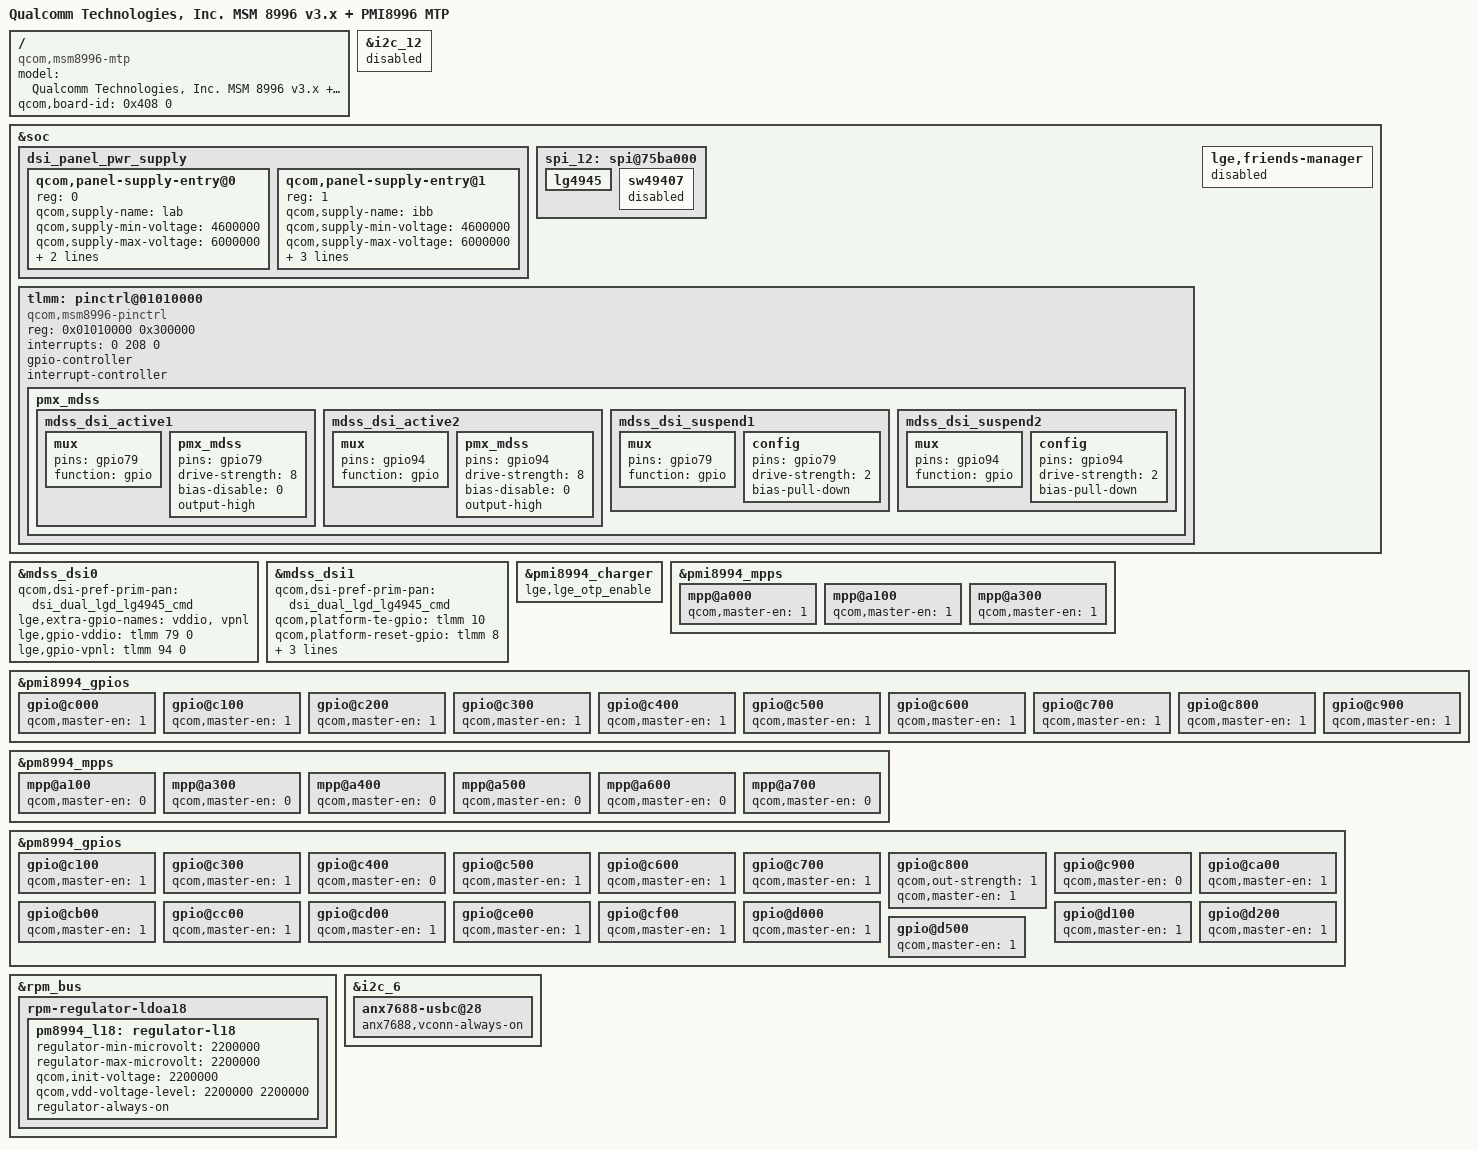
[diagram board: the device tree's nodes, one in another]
/* Copyright (c) 2015, The Linux Foundation. All rights reserved.
 *
 * This program is free software; you can redistribute it and/or modify
 * it under the terms of the GNU General Public License version 2 and
 * only version 2 as published by the Free Software Foundation.
 *
 * This program is distributed in the hope that it will be useful,
 * but WITHOUT ANY WARRANTY; without even the implied warranty of
 * MERCHANTABILITY or FITNESS FOR A PARTICULAR PURPOSE.  See the
 * GNU General Public License for more details.
 */


/dts-v1/;

#include "../../qcom/msm8996-v3.dtsi"
#include "../../qcom/msm-pmi8996.dtsi"
#include "msm8996-elsa_clr_pr.dtsi"
#include "msm8996-elsa_clr_pr-touch.dtsi"
#include "../msm8996-camera/msm8996-elsa-camera.dtsi"
#include "../msm8996-elsa_storage_type/current_storage_type.dtsi"
#include "../msm8996-sound/msm8996-elsa-sound_rev-0_1.dtsi"


/ {
	model = "Qualcomm Technologies, Inc. MSM 8996 v3.x + PMI8996 MTP";
	compatible = "qcom,msm8996-mtp", "qcom,msm8996", "qcom,mtp";
	qcom,board-id = <0x408 0>;
};

&i2c_12 {
	status = "disabled";
};

/* Display Function */
&soc {
	dsi_panel_pwr_supply: dsi_panel_pwr_supply {
		#address-cells = <1>;
		#size-cells = <0>;

		qcom,panel-supply-entry@0 {
			reg = <0>;
			qcom,supply-name = "lab";
			qcom,supply-min-voltage = <4600000>;
			qcom,supply-max-voltage = <6000000>;
			qcom,supply-enable-load = <100000>;
			qcom,supply-disable-load = <100>;
		};

		qcom,panel-supply-entry@1 {
			reg = <1>;
			qcom,supply-name = "ibb";
			qcom,supply-min-voltage = <4600000>;
			qcom,supply-max-voltage = <6000000>;
			qcom,supply-enable-load = <100000>;
			qcom,supply-disable-load = <100>;
			qcom,supply-post-on-sleep = <20>;
		};
	};

	spi_12: spi@75ba000{    /* BLSP-2 QUP6 */
		lg4945 {
			status = "ok";
		};
		sw49407 {
			status = "disabled";
		};
	};
};

&mdss_dsi0 {
	qcom,dsi-pref-prim-pan = <&dsi_dual_lgd_lg4945_cmd>;
	lge,extra-gpio-names = "vddio", "vpnl";

	lge,gpio-vddio = <&tlmm 79 0>;
	lge,gpio-vpnl = <&tlmm 94 0>;
};

&mdss_dsi1 {
	qcom,dsi-pref-prim-pan = <&dsi_dual_lgd_lg4945_cmd>;
	qcom,platform-te-gpio = <&tlmm 10 0>;
	qcom,platform-reset-gpio = <&tlmm 8 0>;

	/delete-property/vddio-supply;
	lge,extra-gpio-names = "vddio", "vpnl";

	lge,gpio-vddio = <&tlmm 79 0>;
	lge,gpio-vpnl = <&tlmm 94 0>;
};

/* pinctrl for Display function
 * GPIO79 : LCD_VDD_IO_EN
 * GPIO94 : LCD_VCL_EN
 */
&soc {
	tlmm: pinctrl@01010000 {
		compatible = "qcom,msm8996-pinctrl";
		reg = <0x01010000 0x300000>;
		interrupts = <0 208 0>;
		gpio-controller;
		#gpio-cells = <2>;
		interrupt-controller;
		#interrupt-cells = <2>;

		pmx_mdss: pmx_mdss {
			mdss_dsi_active1: mdss_dsi_active1 {
				mux {
					pins = "gpio79";
					function = "gpio";
				};

				pmx_mdss {
					pins = "gpio79";
					drive-strength = <8>; /* 8 mA */
					bias-disable = <0>; /* no pull */
					output-high;
				};
			};
			mdss_dsi_active2: mdss_dsi_active2 {
				mux {
					pins = "gpio94";
					function = "gpio";
				};

				pmx_mdss {
					pins = "gpio94";
					drive-strength = <8>; /* 8 mA */
					bias-disable = <0>; /* no pull */
					output-high;
				};
			};
			mdss_dsi_suspend1: mdss_dsi_suspend1 {
				mux {
					pins = "gpio79";
					function = "gpio";
				};

				config {
					pins = "gpio79";
					drive-strength = <2>; /* 2 mA */
					bias-pull-down; /* pull down */
				};
			};
			mdss_dsi_suspend2: mdss_dsi_suspend2 {
				mux {
					pins = "gpio94";
					function = "gpio";
				};

				config {
					pins = "gpio94";
					drive-strength = <2>; /* 2 mA */
					bias-pull-down; /* pull down */
				};
			};
		};
	};
};

&soc {
	lge,friends-manager {
		status = "disabled";
	};
};

&pmi8994_charger {
    lge,lge_otp_enable;
};

/* set unused and changed assigne gpios on here */
&pmi8994_mpps {
/* Must not define the mpp(mpp 3) on here */
	mpp@a000 {	/* MPP 1 VBACKUP_ADC */
		qcom,master-en = <1>;		/* Enable GPIO */
		status = "okay";
	};

	mpp@a100 { /* MPP 2 - FLASH_STROBE_TRIG */
		qcom,master-en = <1>;		/* Enable GPIO */
		status = "okay";
	};

	mpp@a300 { /* MPP 4 - BAT2_THERM */
		qcom,master-en = <1>;		/* Enable GPIO */
		status = "okay";
	};
};

&pmi8994_gpios {
	gpio@c000 { /* GPIO 1 - BOOST_BYP_BYP */
		qcom,master-en = <1>;		/* Enable GPIO */
		status = "okay";
	};

	gpio@c100 { /* GPIO 2 - HIFI_RESET_N */
		qcom,master-en = <1>;		/* Enable GPIO */
		status = "okay";
	};

	gpio@c200 {	/* GPIO 3 SPKR_AMP_EN2 */
		qcom,master-en = <1>;		/* Enable GPIO */
		status = "okay";
	};

	gpio@c300 { /* GPIO 4 - EIS_LDO_EN */
		qcom,master-en = <1>;		/* Enable GPIO */
		status = "okay";
	};

	gpio@c400 { /* GPIO 5 - SWAP_CTRL */
		qcom,master-en = <1>;		/* Enable GPIO */
		status = "okay";
	};

	gpio@c500 { /* GPIO 6 - EIS_GYRO_INT */
		qcom,master-en = <1>;		/* Enable GPIO */
		status = "okay";
	};

	gpio@c600 { /* GPIO 7 - 2ND_CHG_ENABLE_N */
		qcom,master-en = <1>;		/* Enable GPIO */
		status = "okay";
	};

	gpio@c700 { /* GPIO 8 - IRCC_RESET_N */
		qcom,master-en = <1>;		/* Enable GPIO */
		status = "okay";
	};

	gpio@c800 { /* GPIO 9 - 5V_APPSPORT_BOOST_EN */
		qcom,master-en = <1>;		/* Enable GPIO */
		status = "okay";
	};

	gpio@c900 { /* GPIO 10 - EIS_CAM_SELECT */
		qcom,master-en = <1>;		/* Enable GPIO */
		status = "okay";
	};
};

&pm8994_mpps {
/* Must not define the mpps(mpp 1 and 3) on here */
	mpp@a100 { /* MPP 2 - NC */
		qcom,master-en = <0>;		/* Disable GPIO */
		status = "okay";
	};

	mpp@a300 { /* MPP 4 - NC */
		qcom,master-en = <0>;		/* Disable GPIO */
		status = "okay";
	};

	mpp@a400 { /* MPP 5 - NC */
		qcom,master-en = <0>;		/* Disable GPIO */
		status = "okay";
	};

	mpp@a500 { /* MPP 6 - NC */
		qcom,master-en = <0>;		/* Disable GPIO */
		status = "okay";
	};

	mpp@a600 { /* MPP 7 - NC */
		qcom,master-en = <0>;		/* Disable GPIO */
		status = "okay";

	};

	mpp@a700 { /* MPP 8 - NC */
		qcom,master-en = <0>;		/* Disable GPIO */
		status = "okay";
	};
};

&pm8994_gpios {
/* Gpio 1 and 3 is set on relevant usb-type-c */
/* at "kernel\arch\arm64\boot\dts\lge\msm8996-usb-typec-anx7418.dtsi" */
/* Must not define the gpios(gpio 20 and 21) on here */
	gpio@c100 { /* GPIO 2 - VOL_UP_EN */
		qcom,master-en = <1>;		/* Enable GPIO */
		status = "okay";
	};

	gpio@c300 { /* GPIO 4 - TOUCH_KEY_EN */
		qcom,master-en = <1>;		/* Enable GPIO */
		status = "okay";
	};

	gpio@c400 { /* GPIO 5 - NC */
		qcom,master-en = <0>;		/* Disable GPIO */
		status = "okay";
	};

	gpio@c500 { /* GPIO 6 - MENU_KEY_TOUCH_PM */
		qcom,master-en = <1>;		/* Enable GPIO */
		status = "okay";
	};

	gpio@c600 { /* GPIO 7 - BACK_KEY_TOUCH_PM */
		qcom,master-en = <1>;		/* Enable GPIO */
		status = "okay";
	};

	gpio@c700 { /* GPIO 8 - WLAN_POWER_EN */
		qcom,master-en = <1>;		/* Enable GPIO */
		status = "okay";
	};

	gpio@c800 { /* GPIO 9 - HIFI_HPH_SW */
		qcom,out-strength = <1>;	/* Low */
		qcom,master-en = <1>;		/* Enable GPIO */
		status = "okay";
	};

	gpio@c900 { /* GPIO 10 - NC */
		qcom,master-en = <0>;		/* Disable GPIO */
		status = "okay";
	};

	gpio@ca00 { /* GPIO 11 - HIFI_LDO_SW */
		qcom,master-en = <1>;		/* Enable GPIO */
		status = "okay";
	};

	gpio@cb00 { /* GPIO 12 - LCD_AOD_BL_EN */
		qcom,master-en = <1>;		/* Enable GPIO */
		status = "okay";
	};

	gpio@cc00 { /* GPIO 13 - HOME_KEY_PM */
		qcom,master-en = <1>;		/* Enable GPIO */
		status = "okay";
	};

	gpio@cd00 { /* GPIO 14 - APPS_PORT_KEY */
		qcom,master-en = <1>;		/* Enable GPIO */
		status = "okay";
	};

	gpio@ce00 { /* GPIO 15 - CODEC_MCLK */
		qcom,master-en = <1>;		/* Enable GPIO */
		status = "okay";
	};

	gpio@cf00 { /* GPIO 16 - PMI_CLK_IN */
		qcom,master-en = <1>;		/* Enable GPIO */
		status = "okay";
	};

	gpio@d000 { /* GPIO 17 - AOD_RTC */
		qcom,master-en = <1>;		/* Enable GPIO */
		status = "okay";
	};

	gpio@d100 { /* GPIO 18 - WIFI_SLEEP_CLK */
		qcom,master-en = <1>;		/* Enable GPIO */
		status = "okay";
	};

	gpio@d200 { /* GPIO 19 - EXT_ACC_EN */
		qcom,master-en = <1>;		/* Enable GPIO */
		status = "okay";
	};
	gpio@d500 { /* GPIO 22 - LDAF_EN */
		qcom,master-en = <1>;		/* Enable GPIO */
		status = "okay";
	};
};

&rpm_bus {
	rpm-regulator-ldoa18 {
		status = "okay";
		pm8994_l18: regulator-l18 {
			regulator-min-microvolt = <2200000>;
			regulator-max-microvolt = <2200000>;
			qcom,init-voltage       = <2200000>;
			qcom,vdd-voltage-level = <2200000 2200000>;
			regulator-always-on;
			status = "okay";
		};
	};
};

&i2c_6 {
	anx7688-usbc@28 {
		anx7688,vconn-always-on;
	};
};
